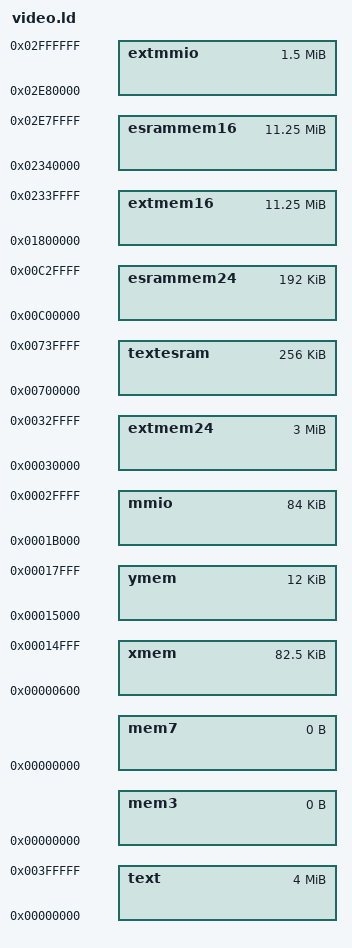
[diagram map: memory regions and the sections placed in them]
/* This file was automatically generated by lcf2ld */

MEMORY
{
	text    	: ORIGIN = 0x00000000*8, LENGTH = 0x00080000*8
	xmem    	: ORIGIN = 0x00000200*3, LENGTH = 0x00006E00*3
	ymem    	: ORIGIN = 0x00007000*3, LENGTH = 0x00001000*3
	mem3    	: ORIGIN = 0x00000000*0, LENGTH = 0x00000000*0 /* Do not use */
	mmio    	: ORIGIN = 0x00009000*3, LENGTH = 0x00007000*3
	extmem24    	: ORIGIN = 0x00010000*3, LENGTH = 0x00100000*3
	extmem16    	: ORIGIN = 0x00800000*3, LENGTH = 0x003C0000*3
	mem7    	: ORIGIN = 0x00000000*0, LENGTH = 0x00000000*0 /* Do not use */
	esrammem24    	: ORIGIN = 0x00400000*3, LENGTH = 0x00010000*3
	esrammem16    	: ORIGIN = 0x00BC0000*3, LENGTH = 0x003C0000*3
	textesram    	: ORIGIN = 0x000E0000*8, LENGTH = 0x00008000*8
	extmmio    	: ORIGIN = 0x00F80000*3, LENGTH = 0x00080000*3
}

/* Used to define __max<T>_ symbols in default linker script.
 * Must be kept coherent with the memory description above. */
DEFAULT_MIN_TEXT	= 0x00000000 /* *8 */;
DEFAULT_MAX_TEXT	= 0x0007FFFF /* *8 */;
DEFAULT_MIN_XMEM	= 0x00000200 /* *3 */;
DEFAULT_MAX_XMEM	= 0x00006FFF /* *3 */;
DEFAULT_MIN_YMEM	= 0x00007000 /* *3 */;
DEFAULT_MAX_YMEM	= 0x00007FFF /* *3 */;
DEFAULT_MIN_MEM3	= 0x00000000 /* *0 */;
DEFAULT_MAX_MEM3	= 0x00000000 /* *0 */;
DEFAULT_MIN_MMIO	= 0x00009000 /* *3 */;
DEFAULT_MAX_MMIO	= 0x0000FFFF /* *3 */;
DEFAULT_MIN_EXTMEM24	= 0x00010000 /* *3 */;
DEFAULT_MAX_EXTMEM24	= 0x0010FFFF /* *3 */;
DEFAULT_MIN_EXTMEM16	= 0x00800000 /* *3 */;
DEFAULT_MAX_EXTMEM16	= 0x00BBFFFF /* *3 */;
DEFAULT_MIN_MEM7	= 0x00000000 /* *0 */;
DEFAULT_MAX_MEM7	= 0x00000000 /* *0 */;
DEFAULT_MIN_ESRAMMEM24	= 0x00400000 /* *3 */;
DEFAULT_MAX_ESRAMMEM24	= 0x0040FFFF /* *3 */;
DEFAULT_MIN_ESRAMMEM16	= 0x00BC0000 /* *3 */;
DEFAULT_MAX_ESRAMMEM16	= 0x00F7FFFF /* *3 */;
DEFAULT_MIN_TEXTESRAM	= 0x000E0000 /* *8 */;
DEFAULT_MAX_TEXTESRAM	= 0x000E7FFF /* *8 */;
DEFAULT_MIN_EXTMMIO	= 0x00F80000 /* *3 */;
DEFAULT_MAX_EXTMMIO	= 0x00FFFFFF /* *3 */;

/* Must be kept coherent with the memory description above. */
__xyconf = 0x0000037F;
